# psoc4100sp256kb register map
Vendor: Cypress Semiconductor; Series: PSoC4100Sp256KB; File version: 1.0
CPU: CM0PLUS r0p1, little endian, MPU, no FPU, VTOR, 2 interrupt priority bits
Registers are 32-bit, read-write, reset 0x0 unless marked. A register's access mark holds for its fields unless they carry their own. Offsets are from the block's base; [hi:lo] are bit positions; 'fields as' and 'values as' point back to an identical list.

## SRSSLT — System Resources Lite Subsystem
Base 0x40030000
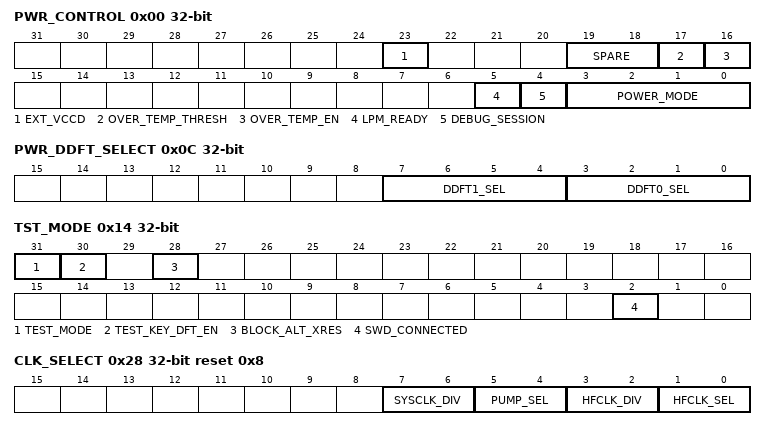
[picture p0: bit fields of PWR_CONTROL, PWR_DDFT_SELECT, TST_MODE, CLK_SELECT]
0x00 PWR_CONTROL — Power Mode Control
  [23] EXT_VCCD — Always write 0 except as noted below. PSoC4-S0 and Streetfighter CapSense products may set this bit if Vccd is provided externally (on Vccd pin). Setting this bit turns off the active regulator and will lead to system reset (BOD) unless both Vddd and Vccd pins are supplied externally. This register bit only resets for XRES, POR, or a detected BOD.
  [19:18] SPARE ro — Spare AHB readback bits that are hooked to PWR_PWRSYS_TRIM1.SPARE_TRIM[1:0] through spare logic equivalent to bitwise inversion. Engineering only.
  [17] OVER_TEMP_THRESH — Over-temperature threshold. 0: TEMP_HIGH condition occurs between 120C and 125C. 1: TEMP_HIGH condition occurs between 60C and 75C (used for testing).
  [16] OVER_TEMP_EN — Enables the die over temperature sensor. Must be enabled when using the TEMP_HIGH interrupt.
  [5] LPM_READY ro — Indicates whether the low power mode regulator is ready to enter DEEPSLEEP mode. 0: If DEEPSLEEP mode is requested, device will enter SLEEP mode. When low power regulators are ready, device will automatically enter the originally requested mode. 1: Normal operation. DEEPSLEEP works as described.
  [4] DEBUG_SESSION ro — Indicates whether a debug session is active (CDBGPWRUPREQ signal is 1)
    0=NO_SESSION (No debug session active); 1=SESSION_ACTIVE (Debug session is active)
  [3:0] POWER_MODE ro — Current power mode of the device. Note that this field cannot be read in all power modes on actual silicon.
    0=RESET (RESET state); 1=ACTIVE (ACTIVE state); 2=SLEEP (SLEEP state); 3=DEEP_SLEEP (DEEP_SLEEP state)
0x04 PWR_KEY_DELAY reset 0xF8 — Power System Key&Delay Register
  [9:0] WAKEUP_HOLDOFF — Delay to wait for references to settle on wakeup from deepsleep. BOD is ignored and system does not resume until this delay expires. Note that the same delay on POR is hard-coded. The default assumes the output of the predivider is 48MHz + 3 percent. Firmware may scale this setting according to the fastest actual clock frequency that can occur when waking from DEEPSLEEP.
0x0C PWR_DDFT_SELECT — Power DDFT Mode Selection Register
  [7:4] DDFT1_SEL — Select signal for power DDFT output #1
    0=WAKEUP; 1=AWAKE; 2=ACT_POWER_EN; 3=ACT_POWER_UP; 4=ACT_POWER_GOOD; 5=ACT_REF_VALID; 6=ACT_REG_VALID; 7=ACT_COMP_OUT; 8=ACT_TEMP_HIGH; 9=DPSLP_COMP_OUT; 10=DPSLP_POWER_UP; 11=AWAKE_DELAYED; 12=LPM_READY; 13=SLEEPHOLDACK_N; 14=GND (1'b0); 15=PWR (1'b1)
  [3:0] DDFT0_SEL — Select signal for power DDFT output #0
    0=WAKEUP; 1=AWAKE; 2=ACT_POWER_EN; 3=ACT_POWER_UP; 4=ACT_POWER_GOOD; 5=ACT_REF_EN (srss_adft_control_act_ref_en); 6=ACT_COMP_EN (srss_adft_control_act_comp_en); 7=DPSLP_REF_EN (srss_adft_control_dpslp_ref_en); 8=DPSLP_REG_EN (srss_adft_control_dpslp_reg_en); 9=DPSLP_COMP_EN (srss_adft_control_dpslp_comp_en); 10=OVER_TEMP_EN (pwr_control_over_temp_en); 11=SLEEPHOLDREQ_N; 12=ADFT_BUF_EN; 13=ATPG_OBSERVE (ATPG observe point (no functional purpose)); 14=GND (1'b0); 15=PWR (1'b1)
0x14 TST_MODE — Test Mode Control Register
  [31] TEST_MODE — Setting this bit will prevent BootROM from yielding execution to Flash image. 0: Normal operation mode 1: Test mode (any test mode)
  [30] TEST_KEY_DFT_EN ro — This bit is set when a XRES test mode key is shifted in. It is the value of the test_key_dft_en signal. When this bit is set, the BootROM will not yield execution to the FLASH image (same function as setting TEST_MODE bit below).
  [28] BLOCK_ALT_XRES — Relevant only for parts that have the alternate XRES mechanism of overloading a GPIO pin temporarily as alternate XRES during test. When set, this bit blocks the alternate XRES function, such that the pin can be used for normal I/O or for ddft/adft observation. See SAS Part-V and Part-IX for details. This register bit only resets for XRES, POR, or a detected BOD.
  [2] SWD_CONNECTED ro — 0: SWD not active 1: SWD activated (Line Reset & Connect sequence passed) (Note: this bit replaces TST_CTRL.SWD_CONNECTED and is present in all M0S8 products except TSG4)
0x28 CLK_SELECT reset 0x8 — Clock Select Register
  [7:6] SYSCLK_DIV — Select clk_sys prescaler value.
    0=NO_DIV (clk_sys= clk_hf/1); 1=DIV_BY_2 (clk_sys= clk_hf/2); 2=DIV_BY_4 (clk_sys= clk_hf/4); 3=DIV_BY_8 (clk_sys= clk_hf/8)
  [5:4] PUMP_SEL — Selects clock source for charge pump clock. This clock is not guaranteed to be glitch free when changing any of its sources or settings.
    0=GND (No clock, connect to gnd); 1=IMO (Use main IMO output); 2=HFCLK (Use clk_hf (using selected source after predivider but before prescaler))
  [3:2] HFCLK_DIV — Selects clk_hf predivider value.
    0=NO_DIV (Transparent mode, feed through selected clock source w/o dividing.); 1=DIV_BY_2 (Divide selected clock source by 2); 2=DIV_BY_4 (Divide selected clock source by 4); 3=DIV_BY_8 (Divide selected clock source by 8)
  [1:0] HFCLK_SEL — Selects a source for clk_hf and dsi_in[0]. Note that not all products support all clock sources. Selecting a clock source that is not supported will result in undefined behavior.
    0=IMO (IMO - Internal R/C Oscillator); 1=EXTCLK (EXTCLK - External Clock Pin); 2=ECO (ECO - External-Crystal Oscillator or PLL subsystem output)
0x2C CLK_ILO_CONFIG reset 0x80000000 — ILO Configuration
  [31] ENABLE — Master enable for ILO oscillator. This bit is hardware set whenever the WDT_DISABLE_KEY is not set to the magic value.
0x30 CLK_IMO_CONFIG reset 0x80000000 — IMO Configuration
  [31] ENABLE — Master enable for IMO oscillator. Clearing this bit will disable the IMO. Don't do this if the system is running off it.
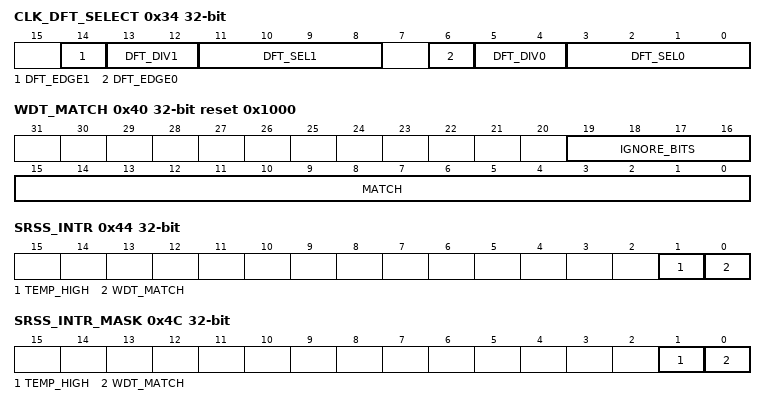
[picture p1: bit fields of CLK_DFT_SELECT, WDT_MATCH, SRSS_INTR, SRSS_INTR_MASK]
0x34 CLK_DFT_SELECT — Clock DFT Mode Selection Register
  [14] DFT_EDGE1 — Edge sensitivity for in-line divider on output #1 (only relevant when DIV1>0).
    0=POSEDGE (Use posedge for divider); 1=NEGEDGE (Use negedge for divider)
  [13:12] DFT_DIV1 — DFT Output Divide Down.
    0=NO_DIV (Direct Output); 1=DIV_BY_2 (Divide by 2); 2=DIV_BY_4 (Divide by 4); 3=DIV_BY_8 (Divide by 8)
  [11:8] DFT_SEL1 — Select signal for DFT output #1
    0=NC (Disabled - output is 0); 1=ILO (clk_ilo: ILO output); 2=IMO (clk_imo: IMO primary output); 3=ECO (clk_eco: ECO output); 4=EXTCLK (clk_ext: external clock input); 5=HFCLK (clk_hf: root of the high-speed clock tree); 6=LFCLK (clk_lf: root of the low-speed clock tree); 7=SYSCLK (clk_sys: root of the CPU/AHB clock tree (gated version of clk_hf)); 8=PUMPCLK (clk_pump: clock provided to charge pumps in FLASH and PA); 9=SLPCTRLCLK (clk_slpctrl: clock provided to SleepController)
  [6] DFT_EDGE0 — Edge sensitivity for in-line divider on output #0 (only relevant when DIV0>0).
    values as DFT_EDGE1
  [5:4] DFT_DIV0 — DFT Output Divide Down.
    values as DFT_DIV1
  [3:0] DFT_SEL0 — Select signal for DFT output #0
    values as DFT_SEL1
0x38 WDT_DISABLE_KEY — Watchdog Disable Key Register
  [31:0] KEY — Disables WDT reset when equal to 0xACED8865. The WDT reset functions normally for any other setting.
0x3C WDT_COUNTER ro — Watchdog Counter Register
  [15:0] COUNTER — Current value of WDT Counter
0x40 WDT_MATCH reset 0x1000 — Watchdog Match Register
  [19:16] IGNORE_BITS — The number of MSB bits of the watchdog timer that are NOT checked against MATCH. This value provides control over the time-to-reset of the watchdog (which happens after 3 successive matches). Note that certain products may enforce a minimum value for this register through design time configuration.
  [15:0] MATCH — Match value for Watchdog counter. Every time WDT_COUNTER reaches MATCH an interrupt is generated. Two unserviced interrupts will lead to a system reset (i.e. at the third match).
0x44 SRSS_INTR — SRSS Interrupt Register
  [1] TEMP_HIGH — Regulator over-temp interrupt. This interrupt can occur when a short circuit exists on the vccd pin or when extreme loads are applied on IO-cells causing the die to overheat. Firmware is encourage to shutdown all IO cells and then go to DeepSleep mode when this interrupt occurs if protection against such conditions is desired.
  [0] WDT_MATCH — WDT Interrupt Request. This bit is set each time WDT_COUNTR==WDT_MATCH. Clearing this bit also feeds the watch dog. Missing 2 interrupts in a row will generate brown-out reset. Due to internal synchronization, it takes 2 SYSCLK cycles to update after a W1C.
0x48 SRSS_INTR_SET — SRSS Interrupt Set Register
  [1] TEMP_HIGH — Writing 1 to this bit internally sets the overtemp interrupt. This can be observed by reading SRSS_INTR.TEMP_HIGH. This bit always reads back as zero.
0x4C SRSS_INTR_MASK — SRSS Interrupt Mask Register
  [1] TEMP_HIGH — Masks REG_OVERTEMP interrupt
  [0] WDT_MATCH — Clearing this bit will not forward the interrupt to the CPU. It will not, however, disable the WDT reset generation on 2 missed interrupts.
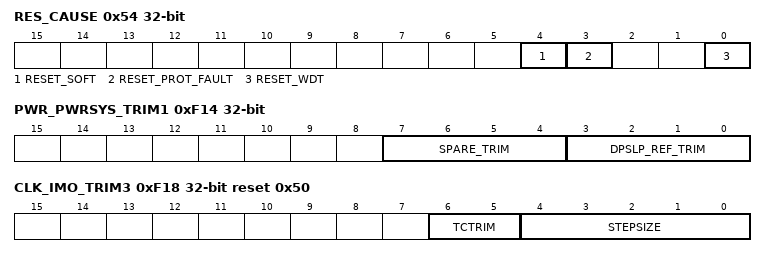
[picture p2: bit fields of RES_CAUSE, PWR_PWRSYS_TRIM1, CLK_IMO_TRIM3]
0x54 RES_CAUSE — Reset Cause Observation Register
  [4] RESET_SOFT — Cortex-M0 requested a system reset through it's SYSRESETREQ. This can be done via a debugger probe or in firmware.
  [3] RESET_PROT_FAULT — A protection violation occurred that requires a RESET. This includes, but is not limited to, hitting a debug breakpoint while in Privileged Mode.
  [0] RESET_WDT — A WatchDog Timer reset has occurred since last power cycle.
0xF00 PWR_BG_TRIM1 reset 0x10 — Bandgap Trim Register
  [5:0] REF_VTRIM — Trims the bandgap reference voltage output. Used to trim the VBG to the voltage where its temperature curvature is minimal. Bit [5] is unused within the bandgap block.
0xF04 PWR_BG_TRIM2 reset 0x1C — Bandgap Trim Register
  [5:0] REF_ITRIM — Trims the bandgap reference current output. Used to trim the IBG to the voltage where its temperature curvature is minimal.
0xF08 CLK_IMO_SELECT — IMO Frequency Select Register
  [2:0] FREQ — Select operating frequency
    0=24_MHZ (IMO runs at 24 MHz); 1=28_MHZ (IMO runs at 28 MHz); 2=32_MHZ (IMO runs at 32 MHz); 3=36_MHZ (IMO runs at 36 MHz); 4=40_MHZ (IMO runs at 40 MHz); 5=44_MHZ (IMO runs at 44 MHz); 6=48_MHZ (IMO runs at 48 MHz)
0xF0C CLK_IMO_TRIM1 reset 0x80 — IMO Trim Register
  [7:0] OFFSET — Frequency trim bits. These bits are determined at manufacturing time for each FREQ setting in CLK_IMO_SELECT and stored in SFLASH. This field is hardware updated during USB osclock mode or when a WCO uses this mechanism for PLL locking the WCO. This is only available with devices that have either USB or a WCO. This field is mapped to the most significant bits of the IMO trim imo_clk_trim[10:3]. The step size of 1 LSB on this field is approximately 120 kHz.
0xF10 CLK_IMO_TRIM2 — IMO Trim Register
  [2:0] FSOFFSET — Frequency trim bits. These bits are not trimmed during manufacturing and kept at 0 under normal operation. This field is hardware updated during USB osclock mode or when a WCO uses this mechanism for PLL locking the WCO. This is only available with devices that have either USB or a WCO. . This field is mapped to the least significant bits of the IMO trim imo_clk_trim[2:0]. The step size of 1 LSB on this field is approximately 15 kHz.
0xF14 PWR_PWRSYS_TRIM1 — Power System Trim Register
  [7:4] SPARE_TRIM — Active-Reference temperature compensation trim (repurposed from spare bits). Bits [7:6] - trim the Active-Reference IREF temperature coefficient (TC). 00: TC = 0 (unchanged) 01: TC = +80ppm/C 10: TC = -80ppm/C 11: TC = -150ppm/C Bits [5:4] - trim the Active-Reference VREF temperature coefficient (TC). 00: TC = 0 (unchanged) 01: TC = -50ppm/C 10: TC = -80ppm/C 11: TC = +150ppm/C
  [3:0] DPSLP_REF_TRIM — Trims the DeepSleep reference that is used by the DeepSleep regulator and DeepSleep power comparator.
0xF18 CLK_IMO_TRIM3 reset 0x50 — IMO Trim Register
  [6:5] TCTRIM — IMO temperature compesation trim. These bits are determined at manufacturing time to adjust for temperature dependence. This bits are dependent on frequency and need to be changed using the Cypress provided frequency change algorithm.
  [4:0] STEPSIZE — IMO trim stepsize bits. These bits are determined at manufacturing time to adjust for process variation. They are used to tune the stepsize of the FSOFFSET and OFFSET trims.

## Notices in the file
(c) (2016-2021), Cypress Semiconductor Corporation (an Infineon company)
or an affiliate of Cypress Semiconductor Corporation.
SPDX-License-Identifier: Apache-2.0
Licensed under the Apache License, Version 2.0 (the "License");
you may not use this file except in compliance with the License.
You may obtain a copy of the License at
http://www.apache.org/licenses/LICENSE-2.0
Unless required by applicable law or agreed to in writing, software
distributed under the License is distributed on an "AS IS" BASIS,
WITHOUT WARRANTIES OR CONDITIONS OF ANY KIND, either express or implied.
See the License for the specific language governing permissions and
limitations under the License.
